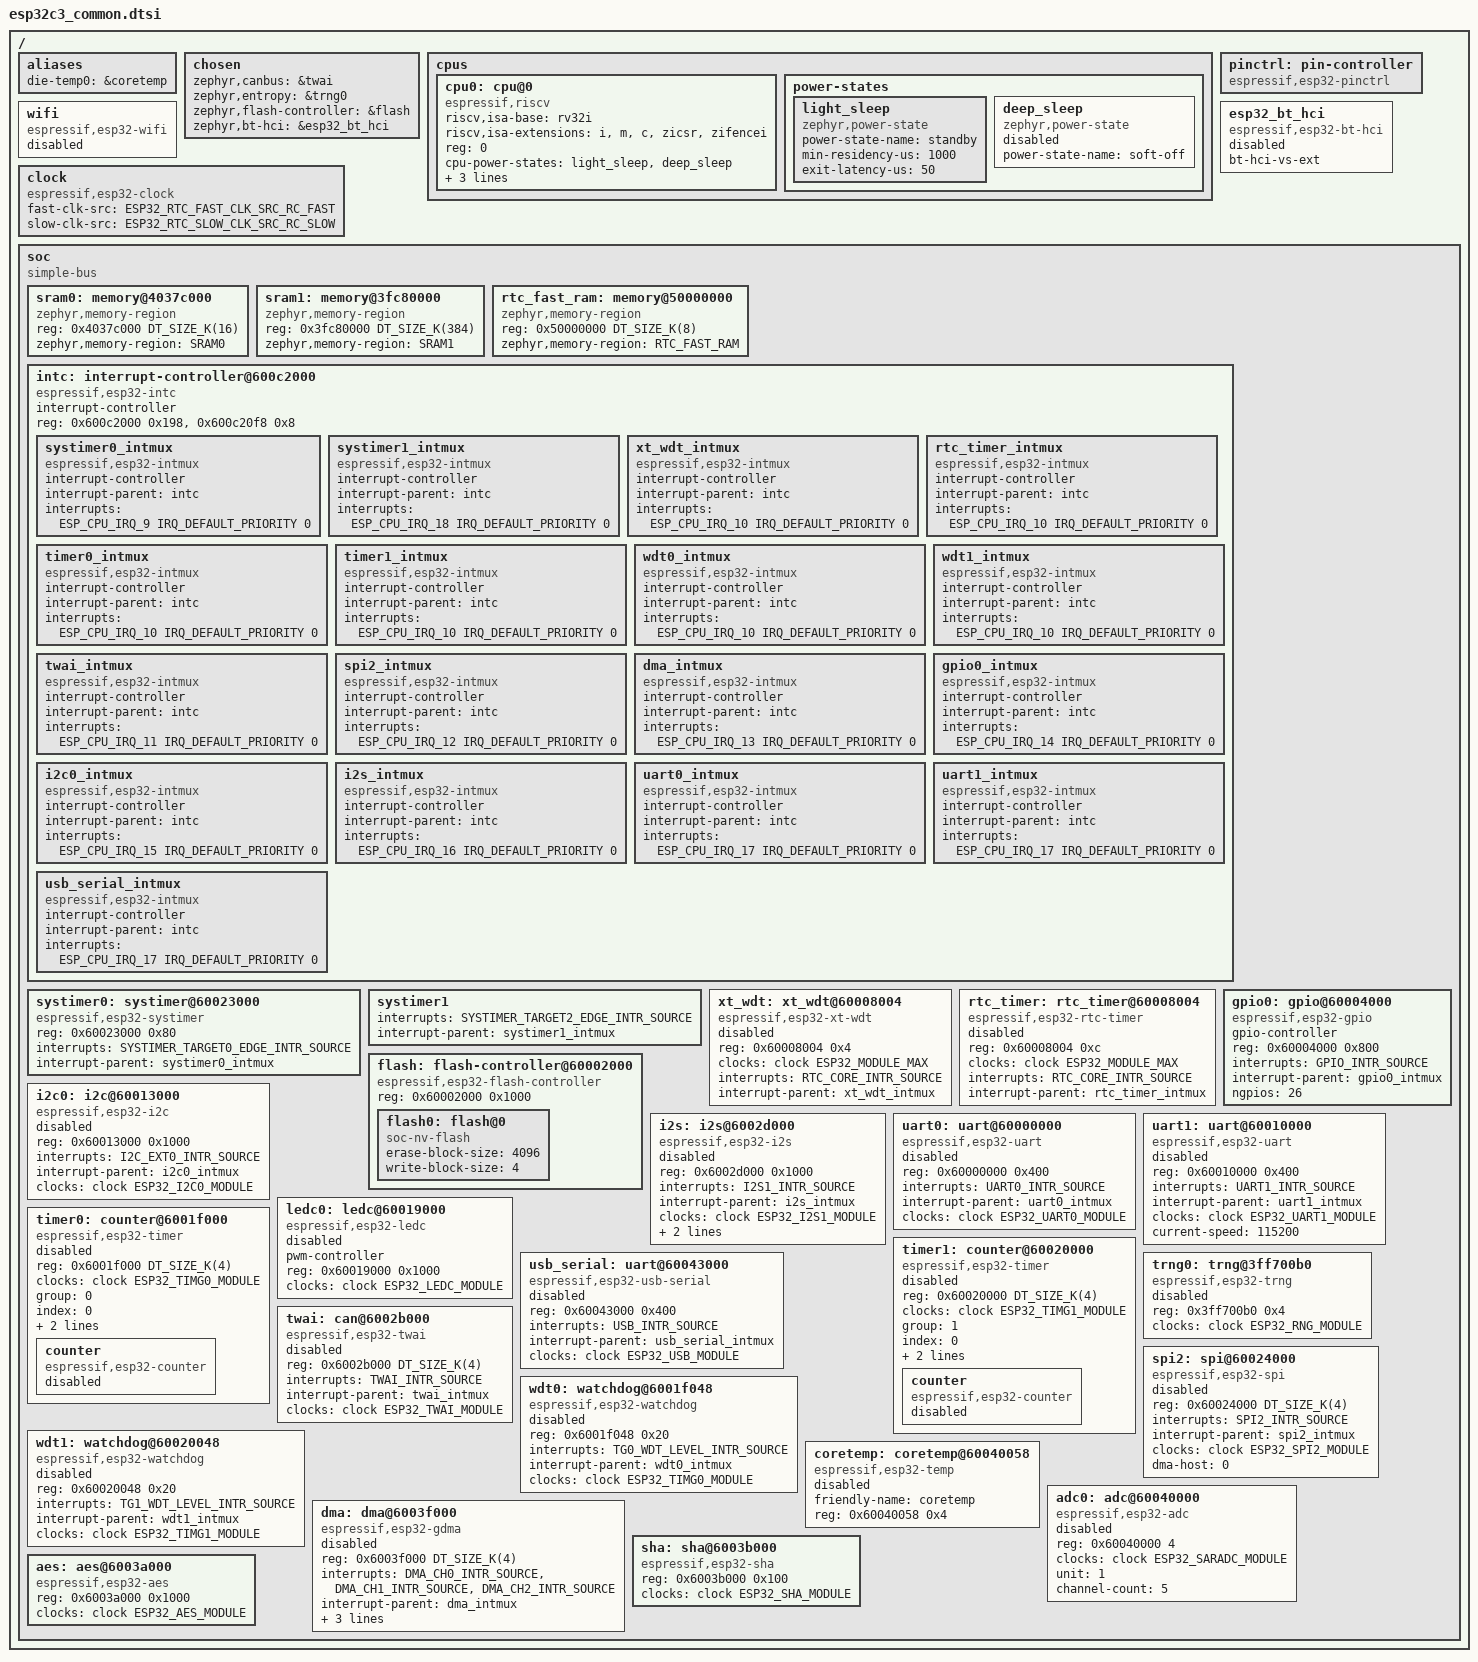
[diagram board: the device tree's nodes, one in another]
/*
 * Copyright (c) 2021 Espressif Systems (Shanghai) Co., Ltd.
 *
 * SPDX-License-Identifier: Apache-2.0
 */
#include <mem.h>
#include <freq.h>
#include <zephyr/dt-bindings/adc/adc.h>
#include <zephyr/dt-bindings/gpio/gpio.h>
#include <zephyr/dt-bindings/i2c/i2c.h>
#include <zephyr/dt-bindings/interrupt-controller/espressif-esp32c3-intmux.h>
#include <zephyr/dt-bindings/clock/esp32c3_clock.h>
#include <zephyr/dt-bindings/pinctrl/esp32-pinctrl.h>

/ {
	#address-cells = <1>;
	#size-cells = <1>;

	aliases {
		die-temp0 = &coretemp;
	};

	chosen {
		zephyr,canbus = &twai;
		zephyr,entropy = &trng0;
		zephyr,flash-controller = &flash;
		zephyr,bt-hci = &esp32_bt_hci;
	};

	cpus {
		#address-cells = <1>;
		#size-cells = <0>;

		cpu0: cpu@0 {
			device_type = "cpu";
			compatible = "espressif,riscv", "riscv";
			riscv,isa-base = "rv32i";
			riscv,isa-extensions = "i", "m", "c", "zicsr", "zifencei";
			reg = <0>;
			cpu-power-states = <&light_sleep &deep_sleep>;
			clock-source = <ESP32_CPU_CLK_SRC_PLL>;
			clock-frequency = <DT_FREQ_M(160)>;
			xtal-freq = <DT_FREQ_M(40)>;
		};

		power-states {
			light_sleep: light_sleep {
				compatible = "zephyr,power-state";
				power-state-name = "standby";
				min-residency-us = <1000>;
				exit-latency-us = <50>;
			};

			deep_sleep: deep_sleep {
				/* Deep sleep must be entered using pm_state_force()
				 * or sys_poweroff() calls only
				 */
				compatible = "zephyr,power-state";
				power-state-name = "soft-off";
				status = "disabled";
			};
		};
	};

	pinctrl: pin-controller {
		compatible = "espressif,esp32-pinctrl";
		status = "okay";
	};

	wifi: wifi {
		compatible = "espressif,esp32-wifi";
		status = "disabled";
	};

	esp32_bt_hci: esp32_bt_hci {
		compatible = "espressif,esp32-bt-hci";
		bt-hci-vs-ext;
		status = "disabled";
	};

	clock: clock {
		compatible = "espressif,esp32-clock";
		fast-clk-src = <ESP32_RTC_FAST_CLK_SRC_RC_FAST>;
		slow-clk-src = <ESP32_RTC_SLOW_CLK_SRC_RC_SLOW>;
		#clock-cells = <1>;
		status = "okay";
	};

	soc {
		#address-cells = <1>;
		#size-cells = <1>;
		compatible = "simple-bus";
		ranges;

		sram0: memory@4037c000 {
			compatible = "zephyr,memory-region", "mmio-sram";
			reg = <0x4037c000 DT_SIZE_K(16)>;
			zephyr,memory-region = "SRAM0";
		};

		sram1: memory@3fc80000 {
			compatible = "zephyr,memory-region", "mmio-sram";
			reg = <0x3fc80000 DT_SIZE_K(384)>;
			zephyr,memory-region = "SRAM1";
		};

		rtc_fast_ram: memory@50000000 {
			compatible = "zephyr,memory-region", "mmio-sram";
			reg = <0x50000000 DT_SIZE_K(8)>;
			zephyr,memory-region = "RTC_FAST_RAM";
		};

		intc: interrupt-controller@600c2000 {
			compatible = "espressif,esp32-intc";
			#address-cells = <0>;
			#interrupt-cells = <3>;
			interrupt-controller;
			/* INTMUX MAP base then pending-STATUS base */
			reg = <0x600c2000 0x198>, <0x600c20f8 0x8>;
			reg-names = "map0", "status0";
			status = "okay";

			systimer0_intmux: systimer0_intmux {
				compatible = "espressif,esp32-intmux";
				interrupt-controller;
				#interrupt-cells = <1>;
				interrupt-parent = <&intc>;
				interrupts = <ESP_CPU_IRQ_9 IRQ_DEFAULT_PRIORITY 0>;
			};

			systimer1_intmux: systimer1_intmux {
				compatible = "espressif,esp32-intmux";
				interrupt-controller;
				#interrupt-cells = <1>;
				interrupt-parent = <&intc>;
				interrupts = <ESP_CPU_IRQ_18 IRQ_DEFAULT_PRIORITY 0>;
			};

			xt_wdt_intmux: xt_wdt_intmux {
				compatible = "espressif,esp32-intmux";
				interrupt-controller;
				#interrupt-cells = <1>;
				interrupt-parent = <&intc>;
				interrupts = <ESP_CPU_IRQ_10 IRQ_DEFAULT_PRIORITY 0>;
			};

			rtc_timer_intmux: rtc_timer_intmux {
				compatible = "espressif,esp32-intmux";
				interrupt-controller;
				#interrupt-cells = <1>;
				interrupt-parent = <&intc>;
				interrupts = <ESP_CPU_IRQ_10 IRQ_DEFAULT_PRIORITY 0>;
			};

			timer0_intmux: timer0_intmux {
				compatible = "espressif,esp32-intmux";
				interrupt-controller;
				#interrupt-cells = <1>;
				interrupt-parent = <&intc>;
				interrupts = <ESP_CPU_IRQ_10 IRQ_DEFAULT_PRIORITY 0>;
			};

			timer1_intmux: timer1_intmux {
				compatible = "espressif,esp32-intmux";
				interrupt-controller;
				#interrupt-cells = <1>;
				interrupt-parent = <&intc>;
				interrupts = <ESP_CPU_IRQ_10 IRQ_DEFAULT_PRIORITY 0>;
			};

			wdt0_intmux: wdt0_intmux {
				compatible = "espressif,esp32-intmux";
				interrupt-controller;
				#interrupt-cells = <1>;
				interrupt-parent = <&intc>;
				interrupts = <ESP_CPU_IRQ_10 IRQ_DEFAULT_PRIORITY 0>;
			};

			wdt1_intmux: wdt1_intmux {
				compatible = "espressif,esp32-intmux";
				interrupt-controller;
				#interrupt-cells = <1>;
				interrupt-parent = <&intc>;
				interrupts = <ESP_CPU_IRQ_10 IRQ_DEFAULT_PRIORITY 0>;
			};

			twai_intmux: twai_intmux {
				compatible = "espressif,esp32-intmux";
				interrupt-controller;
				#interrupt-cells = <1>;
				interrupt-parent = <&intc>;
				interrupts = <ESP_CPU_IRQ_11 IRQ_DEFAULT_PRIORITY 0>;
			};

			spi2_intmux: spi2_intmux {
				compatible = "espressif,esp32-intmux";
				interrupt-controller;
				#interrupt-cells = <1>;
				interrupt-parent = <&intc>;
				interrupts = <ESP_CPU_IRQ_12 IRQ_DEFAULT_PRIORITY 0>;
			};

			dma_intmux: dma_intmux {
				compatible = "espressif,esp32-intmux";
				interrupt-controller;
				#interrupt-cells = <1>;
				interrupt-parent = <&intc>;
				interrupts = <ESP_CPU_IRQ_13 IRQ_DEFAULT_PRIORITY 0>;
			};

			gpio0_intmux: gpio0_intmux {
				compatible = "espressif,esp32-intmux";
				interrupt-controller;
				#interrupt-cells = <1>;
				interrupt-parent = <&intc>;
				interrupts = <ESP_CPU_IRQ_14 IRQ_DEFAULT_PRIORITY 0>;
			};

			i2c0_intmux: i2c0_intmux {
				compatible = "espressif,esp32-intmux";
				interrupt-controller;
				#interrupt-cells = <1>;
				interrupt-parent = <&intc>;
				interrupts = <ESP_CPU_IRQ_15 IRQ_DEFAULT_PRIORITY 0>;
			};

			i2s_intmux: i2s_intmux {
				compatible = "espressif,esp32-intmux";
				interrupt-controller;
				#interrupt-cells = <1>;
				interrupt-parent = <&intc>;
				interrupts = <ESP_CPU_IRQ_16 IRQ_DEFAULT_PRIORITY 0>;
			};

			uart0_intmux: uart0_intmux {
				compatible = "espressif,esp32-intmux";
				interrupt-controller;
				#interrupt-cells = <1>;
				interrupt-parent = <&intc>;
				interrupts = <ESP_CPU_IRQ_17 IRQ_DEFAULT_PRIORITY 0>;
			};

			uart1_intmux: uart1_intmux {
				compatible = "espressif,esp32-intmux";
				interrupt-controller;
				#interrupt-cells = <1>;
				interrupt-parent = <&intc>;
				interrupts = <ESP_CPU_IRQ_17 IRQ_DEFAULT_PRIORITY 0>;
			};

			usb_serial_intmux: usb_serial_intmux {
				compatible = "espressif,esp32-intmux";
				interrupt-controller;
				#interrupt-cells = <1>;
				interrupt-parent = <&intc>;
				interrupts = <ESP_CPU_IRQ_17 IRQ_DEFAULT_PRIORITY 0>;
			};
		};

		systimer0: systimer@60023000 {
			compatible = "espressif,esp32-systimer";
			reg = <0x60023000 0x80>;
			interrupts = <SYSTIMER_TARGET0_EDGE_INTR_SOURCE>;
			interrupt-parent = <&systimer0_intmux>;
			status = "okay";
		};

		/*
		 * esp_timer alarm (SYSTIMER_TARGET2) on its own CPU interrupt line via
		 * systimer1_intmux, so it never shares a source or a CPU line with the
		 * OS tick (systimer0 / TARGET0). Interrupt-only node - the systimer HAL
		 * uses fixed register bases, so no reg is required here.
		 */
		systimer1: systimer1 {
			interrupts = <SYSTIMER_TARGET2_EDGE_INTR_SOURCE>;
			interrupt-parent = <&systimer1_intmux>;
			status = "okay";
		};

		xt_wdt: xt_wdt@60008004 {
			compatible = "espressif,esp32-xt-wdt";
			reg = <0x60008004 0x4>;
			clocks = <&clock ESP32_MODULE_MAX>;
			interrupts = <RTC_CORE_INTR_SOURCE>;
			interrupt-parent = <&xt_wdt_intmux>;
			status = "disabled";
		};

		rtc_timer: rtc_timer@60008004 {
			reg = <0x60008004 0xc>;
			compatible = "espressif,esp32-rtc-timer";
			clocks = <&clock ESP32_MODULE_MAX>;
			interrupts = <RTC_CORE_INTR_SOURCE>;
			interrupt-parent = <&rtc_timer_intmux>;
			status = "disabled";
		};

		flash: flash-controller@60002000 {
			compatible = "espressif,esp32-flash-controller";
			reg = <0x60002000 0x1000>;

			#address-cells = <1>;
			#size-cells = <1>;
			ranges;

			flash0: flash@0 {
				compatible = "soc-nv-flash";
				erase-block-size = <4096>;
				write-block-size = <4>;
				#address-cells = <1>;
				#size-cells = <1>;
				/* reg and ranges are specified in SOC/SIP dtsi */
			};
		};

		gpio0: gpio@60004000 {
			compatible = "espressif,esp32-gpio";
			gpio-controller;
			#gpio-cells = <2>;
			reg = <0x60004000 0x800>;
			interrupts = <GPIO_INTR_SOURCE>;
			interrupt-parent = <&gpio0_intmux>;
			/* Maximum available pins (per port)
			 * Actual occupied pins are specified
			 * on part number dtsi level, using
			 * the `gpio-reserved-ranges` property.
			 */
			ngpios = <26>;   /* 0..25 */
		};

		i2c0: i2c@60013000 {
			compatible = "espressif,esp32-i2c";
			#address-cells = <1>;
			#size-cells = <0>;
			reg = <0x60013000 0x1000>;
			interrupts = <I2C_EXT0_INTR_SOURCE>;
			interrupt-parent = <&i2c0_intmux>;
			clocks = <&clock ESP32_I2C0_MODULE>;
			status = "disabled";
		};

		i2s: i2s@6002d000 {
			compatible = "espressif,esp32-i2s";
			#address-cells = <1>;
			#size-cells = <0>;
			reg = <0x6002d000 0x1000>;
			interrupts = <I2S1_INTR_SOURCE>;
			interrupt-parent = <&i2s_intmux>;
			clocks = <&clock ESP32_I2S1_MODULE>;
			dmas = <&dma 2>, <&dma 3>;
			dma-names = "rx", "tx";
			unit = <0>;
			status = "disabled";
		};

		uart0: uart@60000000 {
			compatible = "espressif,esp32-uart";
			reg = <0x60000000 0x400>;
			status = "disabled";
			interrupts = <UART0_INTR_SOURCE>;
			interrupt-parent = <&uart0_intmux>;
			clocks = <&clock ESP32_UART0_MODULE>;
		};

		uart1: uart@60010000 {
			compatible = "espressif,esp32-uart";
			reg = <0x60010000 0x400>;
			status = "disabled";
			interrupts = <UART1_INTR_SOURCE>;
			interrupt-parent = <&uart1_intmux>;
			clocks = <&clock ESP32_UART1_MODULE>;
			current-speed = <115200>;
		};

		ledc0: ledc@60019000 {
			compatible = "espressif,esp32-ledc";
			pwm-controller;
			#pwm-cells = <3>;
			reg = <0x60019000 0x1000>;
			clocks = <&clock ESP32_LEDC_MODULE>;
			status = "disabled";
		};

		usb_serial: uart@60043000 {
			compatible = "espressif,esp32-usb-serial";
			reg = <0x60043000 0x400>;
			status = "disabled";
			interrupts = <USB_INTR_SOURCE>;
			interrupt-parent = <&usb_serial_intmux>;
			clocks = <&clock ESP32_USB_MODULE>;
		};

		timer0: counter@6001f000 {
			compatible = "espressif,esp32-timer";
			reg = <0x6001f000 DT_SIZE_K(4)>;
			clocks = <&clock ESP32_TIMG0_MODULE>;
			group = <0>;
			index = <0>;
			interrupts = <TG0_T0_LEVEL_INTR_SOURCE>;
			interrupt-parent = <&timer0_intmux>;
			status = "disabled";

			counter {
				compatible = "espressif,esp32-counter";
				status = "disabled";
			};
		};

		timer1: counter@60020000 {
			compatible = "espressif,esp32-timer";
			reg = <0x60020000 DT_SIZE_K(4)>;
			clocks = <&clock ESP32_TIMG1_MODULE>;
			group = <1>;
			index = <0>;
			interrupts = <TG1_T0_LEVEL_INTR_SOURCE>;
			interrupt-parent = <&timer1_intmux>;
			status = "disabled";

			counter {
				compatible = "espressif,esp32-counter";
				status = "disabled";
			};
		};

		trng0: trng@3ff700b0 {
			compatible = "espressif,esp32-trng";
			reg = <0x3ff700b0 0x4>;
			clocks = <&clock ESP32_RNG_MODULE>;
			status = "disabled";
		};

		twai: can@6002b000 {
			compatible = "espressif,esp32-twai";
			reg = <0x6002b000 DT_SIZE_K(4)>;
			interrupts = <TWAI_INTR_SOURCE>;
			interrupt-parent = <&twai_intmux>;
			clocks = <&clock ESP32_TWAI_MODULE>;
			status = "disabled";
		};

		spi2: spi@60024000 {
			compatible = "espressif,esp32-spi";
			reg = <0x60024000 DT_SIZE_K(4)>;
			interrupts = <SPI2_INTR_SOURCE>;
			interrupt-parent = <&spi2_intmux>;
			clocks = <&clock ESP32_SPI2_MODULE>;
			dma-host = <0>;
			status = "disabled";
		};

		wdt0: watchdog@6001f048 {
			compatible = "espressif,esp32-watchdog";
			reg = <0x6001f048 0x20>;
			interrupts = <TG0_WDT_LEVEL_INTR_SOURCE>;
			interrupt-parent = <&wdt0_intmux>;
			clocks = <&clock ESP32_TIMG0_MODULE>;
			status = "disabled";
		};

		wdt1: watchdog@60020048 {
			compatible = "espressif,esp32-watchdog";
			reg = <0x60020048 0x20>;
			interrupts = <TG1_WDT_LEVEL_INTR_SOURCE>;
			interrupt-parent = <&wdt1_intmux>;
			clocks = <&clock ESP32_TIMG1_MODULE>;
			status = "disabled";
		};

		coretemp: coretemp@60040058 {
			compatible = "espressif,esp32-temp";
			friendly-name = "coretemp";
			reg = <0x60040058 0x4>;
			status = "disabled";
		};

		adc0: adc@60040000 {
			compatible = "espressif,esp32-adc";
			reg = <0x60040000 4>;
			clocks = <&clock ESP32_SARADC_MODULE>;
			unit = <1>;
			channel-count = <5>;
			#io-channel-cells = <1>;
			status = "disabled";
		};

		dma: dma@6003f000 {
			compatible = "espressif,esp32-gdma";
			reg = <0x6003f000 DT_SIZE_K(4)>;
			#dma-cells = <1>;
			interrupts = <DMA_CH0_INTR_SOURCE>, <DMA_CH1_INTR_SOURCE>,
				     <DMA_CH2_INTR_SOURCE>;
			interrupt-parent = <&dma_intmux>;
			clocks = <&clock ESP32_GDMA_MODULE>;
			dma-channels = <6>;
			dma-buf-addr-alignment = <4>;
			status = "disabled";
		};

		sha: sha@6003b000 {
			compatible = "espressif,esp32-sha";
			reg = <0x6003b000 0x100>;
			clocks = <&clock ESP32_SHA_MODULE>;
			status = "okay";
		};

		aes: aes@6003a000 {
			compatible = "espressif,esp32-aes";
			reg = <0x6003a000 0x1000>;
			clocks = <&clock ESP32_AES_MODULE>;
			status = "okay";
		};
	};
};
